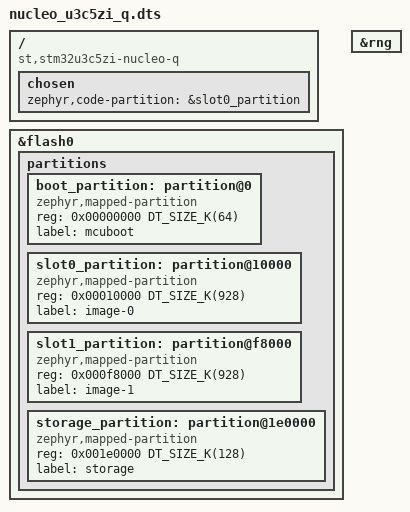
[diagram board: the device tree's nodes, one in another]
/*
 * Copyright (c) 2026 Filip Stojanovic <filipembedded@gmail.com>
 *
 * SPDX-License-Identifier: Apache-2.0
 */

/dts-v1/;
#include "nucleo_u3c5zi_q-common.dts"

/ {
	compatible = "st,stm32u3c5zi-nucleo-q";

	chosen {
		zephyr,code-partition = &slot0_partition;
	};
};

&flash0 {
	partitions {
		ranges;
		#address-cells = <1>;
		#size-cells = <1>;

		/*
		 * Following flash partition is dedicated to the use of nucleo_u3c5zi_q
		 * with TZEN=0 (so w/o TFM).
		 * The board has in total 2048 KiB of flash memory.
		 */
		boot_partition: partition@0 {
			compatible = "zephyr,mapped-partition";
			reg = <0x00000000 DT_SIZE_K(64)>;
			label = "mcuboot";
		};

		slot0_partition: partition@10000 {
			compatible = "zephyr,mapped-partition";
			reg = <0x00010000 DT_SIZE_K(928)>;
			label = "image-0";
		};

		slot1_partition: partition@f8000 {
			compatible = "zephyr,mapped-partition";
			reg = <0x000f8000 DT_SIZE_K(928)>;
			label = "image-1";
		};

		storage_partition: partition@1e0000 {
			compatible = "zephyr,mapped-partition";
			reg = <0x001e0000 DT_SIZE_K(128)>;
			label = "storage";
		};
	};
};

&rng {
	status = "okay";
};
